# ATA5795 device description
Architecture: AVR8; Family: megaAVR
Registers are 8-bit, access not given, no defined reset value unless marked. A register's access mark holds for its fields unless they carry their own. Offsets are from the block's base; [hi:lo] are bit positions.

## AFE
Instances: AFE 0x00
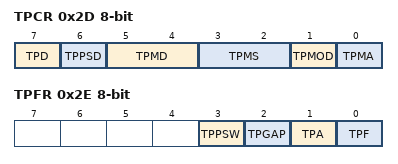
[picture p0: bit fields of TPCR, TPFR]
0x2D TPCR — Transponder Control Register
  [7] TPD — Transponder Disable Bit
  [6] TPPSD — Transponder Power Switch Disable Bit
  [5:4] TPMD — Transponder Modulation Damping level select Bit1
  [3:2] TPMS — Transponder Modulation Select Bits
  [1] TPMOD — Transponder Modulator Bit
  [0] TPMA — Transponder Mode Acknowledgment Bit
0x2E TPFR — Transponder Status & Flag Register
  [3] TPPSW — Transponder Power Switch Bit
  [2] TPGAP — Transponder Gap Signal Bit
  [1] TPA — Transponder Active Bit
  [0] TPF — Transponder Flag
0x9C TPIMR — Transponder Interrupt Mask Register
  [0] TPIM — Transponder Interrupt Mask Bit

## IRLED
Instances: IRLED 0x00
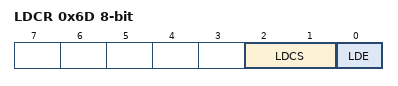
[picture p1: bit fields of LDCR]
0x6D LDCR — LED Driver Control Register
  [2:1] LDCS — LED Driver Current Select Bits
  [0] LDE — LED Driver Enable Bit

## AES
Instances: AES 0x00
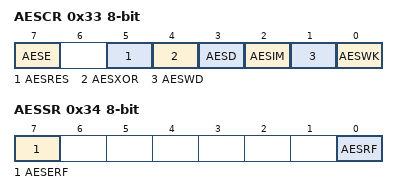
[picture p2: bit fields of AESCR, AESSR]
0x33 AESCR — AES Control Register
  [7] AESE — AES Enable Bit
  [5] AESRES — AES Reset Bit
  [4] AESXOR — AES State XOR load bit
  [3] AESD — AES Direction Bit
  [2] AESIM — AES Interrupt Mask Bit
  [1] AESWD — AES Write Data Bit
  [0] AESWK — AES Write Key Bit
0x34 AESSR — AES Status Register
  [7] AESERF — AES Error Flag Bit
  [0] AESRF — AES Ready Flag Bit
0x49 AESDR — AES Data Register
0x4A AESKR — AES Key Register
  [7:0] AESKR — AES Key Register Bits

## MOD
Instances: MOD 0x00
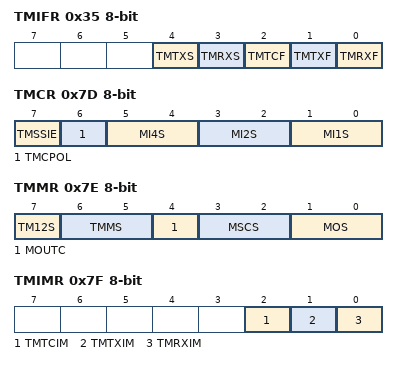
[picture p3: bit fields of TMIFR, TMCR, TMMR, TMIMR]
0x35 TMIFR — Timer Modulator Interrupt Flag Register
  [4] TMTXS — Timer Modulator SSI Transmit Status Bit
  [3] TMRXS — Timer Modulator SSI Receive Status Bit
  [2] TMTCF — Timer Modulator SSI Transmit Complete Flag Bit
  [1] TMTXF — Timer Modulator SSI Transmit Flag Bit
  [0] TMRXF — Timer Modulator SSI Receive Flag Bit
0x48 TMDR — Timer Modulator Data Register
0x7D TMCR — Timer Modulator Control Register
  [7] TMSSIE — Timer Modulator SSI Enable Bit
  [6] TMCPOL — Timer Modulator Clock Polarity for SSI shift clock
  [5:4] MI4S — Modulator Interface 4 Select Bits
  [3:2] MI2S — Modulator Interface 2 Select Bits
  [1:0] MI1S — Modulator Interface 1 Select Bits
0x7E TMMR — Timer Modulator Mode Register
  [7] TM12S — Timer Modulator 1/2 output Select bit
  [6:5] TMMS — Timer Modulator Mode Select Bits
  [4] MOUTC — Modulator OUT signal Complement Bit
  [3:2] MSCS — Modulator Shift Clock Select Bits
  [1:0] MOS — Modulator Output Select Bits
0x7F TMIMR — Timer Modulator Interrupt Mask Register
  [2] TMTCIM — Timer Modulator SSI Transmit Complete Interrupt Mask Bit
  [1] TMTXIM — Timer Modulator SSI Transmit Interrupt Mask Bit
  [0] TMRXIM — Timer Modulator SSI Receive Interrupt Mask Bit
0xA8 TMMDR bits used 3:0 — Timer Modulator Manchester Data Register
0xA9 TMBDR bits used 3:0 — Timer Modulator Biphase Data Register
0xAA TMTDR — Timer Modulator Transmit Data Register
0xAB TMSR — Timer Modulator Shift Register

## VMON
Instances: VMON 0x00
0x36 VMSR — Voltage Monitor Status Register
  [0] VMF — Voltage Monitor Flag
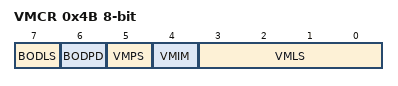
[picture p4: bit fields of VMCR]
0x4B VMCR — Voltage Monitor Control Register
  [7] BODLS — Brown-Out Detection Level Bit
  [6] BODPD — Brown-Out Detection on Power-Down Bit
  [5] VMPS — Voltage Monitor Power Supply Voltage Select Bit
  [4] VMIM — Voltag Monitor Interrupt Mask bit
  [3:0] VMLS — Voltage Monitor Level Select Bits

## EXTERNAL_INTERRUPT
Instances: EXTERNAL_INTERRUPT 0x00
0x37 PCIFR — Pin Change Interrupt Flag Register
  [1:0] PCIF — Pin Change Interrupt Flags
0x3D EIFR — External Interrupt Flag Register
  [0] INTF0 — External Interrupt Flag 0
0x46 PCICR — Pin Change Interrupt Control Register
  [1:0] PCIE — Pin Change Interrupt Enables
0x47 EIMSK — External Interrupt Mask Register
  [0] INT0 — External Interrupt Request 0 Enable
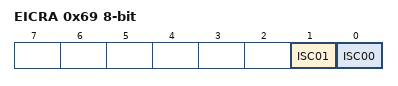
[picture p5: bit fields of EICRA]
0x69 EICRA — External Interrupt Control Register
  [1] ISC01 — External Interrupt Sense Control 0 Bit 1
  [0] ISC00 — External Interrupt Sense Control 0 Bit 0
0x6A PCMSK0 — Pin Change Mask Register 0
  [7:0] PCINT — Pin Change Enable Masks
0x6B PCMSK1 — Pin Change Mask Register 1
  [7:0] PCINT (bit 8 of the value upward) — Pin Change Enable Masks
